AUTOSAR XML (schema 00046)
package /ComponentTypes
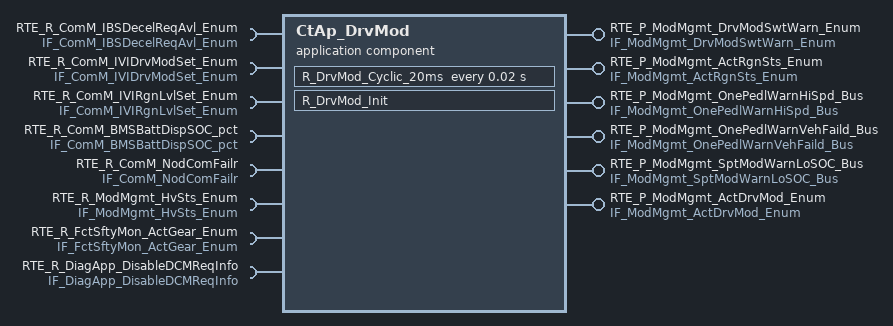
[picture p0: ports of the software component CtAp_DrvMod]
  application sw component type CtAp_DrvMod
    5 x require port:
      RTE_R_ComM_IBSDecelReqAvl_Enum: nonqueued-receiver-com-spec{data-element=tec_ComM_IBSDecelReqAvl_Enum, filter=data-filter-type=ALWAYS, init-value=0}, required-interface=IF_ComM_IBSDecelReqAvl_Enum
      RTE_R_ComM_IVIDrvModSet_Enum: nonqueued-receiver-com-spec{data-element=tec_ComM_IVIDrvModSet_Enum, filter=data-filter-type=ALWAYS, init-value=0}, required-interface=IF_ComM_IVIDrvModSet_Enum
      RTE_R_ComM_IVIRgnLvlSet_Enum: nonqueued-receiver-com-spec{data-element=tec_ComM_IVIRgnLvlSet_Enum, filter=data-filter-type=ALWAYS, init-value=0}, required-interface=IF_ComM_IVIRgnLvlSet_Enum
      RTE_R_ComM_BMSBattDispSOC_pct: nonqueued-receiver-com-spec{data-element=tec_ComM_BMSBattDispSOC_pct, filter=data-filter-type=ALWAYS, init-value=0}, required-interface=IF_ComM_BMSBattDispSOC_pct
      RTE_R_ComM_NodComFailr: required-interface=IF_ComM_NodComFailr
        required-com-specs:
          data-element=tec_ComM_SGWNodComFailr_Flg, filter=data-filter-type=ALWAYS, init-value=0
          data-element=tec_ComM_CGWNodComFailr_Flg, filter=data-filter-type=ALWAYS, init-value=0
          data-element=tec_ComM_TCUNodComFailr_Flg, filter=data-filter-type=ALWAYS, init-value=0
          data-element=tec_ComM_BCMNodComFailr_Flg, filter=data-filter-type=ALWAYS, init-value=0
          data-element=tec_ComM_PRNDNodComFailr_Flg, filter=data-filter-type=ALWAYS, init-value=0
          data-element=tec_ComM_IVINodComFailr_Flg, filter=data-filter-type=ALWAYS, init-value=0
          data-element=tec_ComM_DCDCNodComFailr_Flg, filter=data-filter-type=ALWAYS, init-value=0
          data-element=tec_ComM_OBCNodComFailr_Flg, filter=data-filter-type=ALWAYS, init-value=0
          data-element=tec_ComM_CHIBSNodComFailr_Flg, filter=data-filter-type=ALWAYS, init-value=0
          data-element=tec_ComM_MCUNodComFailr_Flg, filter=data-filter-type=ALWAYS, init-value=0
          data-element=tec_ComM_EVCOMNodComFailr_Flg, filter=data-filter-type=ALWAYS, init-value=0
          data-element=tec_ComM_EPTIBSNodComFailr_Flg, filter=data-filter-type=ALWAYS, init-value=0
          data-element=tec_ComM_DCMNodComFailr_Flg, filter=data-filter-type=ALWAYS, init-value=0
          data-element=tec_ComM_BMSNodComFailr_Flg, filter=data-filter-type=ALWAYS, init-value=0
          data-element=tec_ComM_ACUNodComFailr_Flg, filter=data-filter-type=ALWAYS, init-value=0
          data-element=tec_ComM_APTCNodComFailr_Flg, filter=data-filter-type=ALWAYS, init-value=0
          data-element=tec_ComM_ADCUNodComFailr_Flg, filter=data-filter-type=ALWAYS, init-value=0
          data-element=tec_ComM_DCMRRNodComFailr_Flg, filter=data-filter-type=ALWAYS, init-value=0
          data-element=tec_ComM_DCMRLNodComFailr_Flg, filter=data-filter-type=ALWAYS, init-value=0
          data-element=tec_ComM_DCMFRNodComFailr_Flg, filter=data-filter-type=ALWAYS, init-value=0
          data-element=tec_ComM_DCMFLNodComFailr_Flg, filter=data-filter-type=ALWAYS, init-value=0
          data-element=tec_ComM_SGWCHNodComFailr_Flg, init-value=0
    6 x provide port:
      RTE_P_ModMgmt_DrvModSwtWarn_Enum: nonqueued-sender-com-spec{data-element=tec_ModMgmt_DrvModSwtWarn_Enum, init-value=0}, provided-interface=IF_ModMgmt_DrvModSwtWarn_Enum
      RTE_P_ModMgmt_ActRgnSts_Enum: nonqueued-sender-com-spec{data-element=tec_ModMgmt_ActRgnSts_Enum, init-value=0}, provided-interface=IF_ModMgmt_ActRgnSts_Enum
      RTE_P_ModMgmt_OnePedlWarnHiSpd_Bus: nonqueued-sender-com-spec{data-element=tec_ModMgmt_OnePedlWarnHiSpd_Bus, init-value=fields=[ModMgmt_MonStatOnePedlWarnHiSpd:0, ModMgmt_MonResOnePedlWarnHiSpd:0, ModMgmt_ErrStatOnePedlWarnHiSpd:0, ModMgmt_ErrResOnePedlWarnHiSpd:0]}, provided-interface=IF_ModMgmt_OnePedlWarnHiSpd_Bus
      RTE_P_ModMgmt_OnePedlWarnVehFaild_Bus: nonqueued-sender-com-spec{data-element=tec_ModMgmt_OnePedlWarnVehFaild_Bus, init-value=fields=[ModMgmt_MonStatOnePedlWarnVehFaild:0, ModMgmt_MonResOnePedlWarnVehFaild:0, ModMgmt_ErrStatOnePedlWarnVehFaild:0, ModMgmt_ErrResOnePedlWarnVehFaild:0]}, provided-interface=IF_ModMgmt_OnePedlWarnVehFaild_Bus
      RTE_P_ModMgmt_SptModWarnLoSOC_Bus: nonqueued-sender-com-spec{data-element=tec_ModMgmt_SptModWarnLoSOC_Bus, init-value=fields=[ModMgmt_MonStatSptModWarnLoSOC:0, ModMgmt_MonResSptModWarnLoSOC:0, ModMgmt_ErrStatSptModWarnLoSOC:0, ModMgmt_ErrResSptModWarnLoSOC:0]}, provided-interface=IF_ModMgmt_SptModWarnLoSOC_Bus
      RTE_P_ModMgmt_ActDrvMod_Enum: nonqueued-sender-com-spec{data-element=tec_ModMgmt_ActDrvMod_Enum, init-value=0}, provided-interface=IF_ModMgmt_ActDrvMod_Enum
    require port RTE_R_ModMgmt_HvSts_Enum: nonqueued-receiver-com-spec{data-element=tec_ModMgmt_HvSts_Enum, filter=data-filter-type=ALWAYS, init-value=0}, required-interface=IF_ModMgmt_HvSts_Enum
    provide/require port RTE_RP_ModMgmtInfo:
      nv-provide-com-spec{ram-block-init-value=fields=[ModMgmt_DrvModMemInfo_Enum:2, ModMgmt_ActRgnStsMemInfo_Enum:3], rom-block-init-value=fields=[ModMgmt_DrvModMemInfo_Enum:2, ModMgmt_ActRgnStsMemInfo_Enum:3], variable=tec_ModMgmtInfo}
      nv-require-com-spec{init-value=fields=[ModMgmt_DrvModMemInfo_Enum:2, ModMgmt_ActRgnStsMemInfo_Enum:3], variable=tec_ModMgmtInfo}
      provided-required-interface=IF_ModMgmtInfo
    require port RTE_R_FctSftyMon_ActGear_Enum: nonqueued-receiver-com-spec{data-element=tec_FctSftyMon_ActGear_Enum, filter=data-filter-type=ALWAYS, init-value=0}, required-interface=IF_FctSftyMon_ActGear_Enum
    require port RTE_R_DiagApp_DisableDCMReqInfo: nonqueued-receiver-com-spec{data-element=tec_DiagApp_DisableDCMReqInfo, filter=data-filter-type=ALWAYS, init-value=0}, required-interface=IF_DiagApp_DisableDCMReqInfo
    behavior CtAp_DrvMod_InternalBehavior
      timing event TMT_R_DrvMod_Cyclic_20ms: start-on-event=R_DrvMod_Cyclic_20ms, period=0.02
      init event CtAp_DrvMod_InitEvent: start-on-event=R_DrvMod_Init
      runnable R_DrvMod_Cyclic_20ms
        data-receive-point-by-arguments:
          11 x access:
            REC_RTE_R_ComM_BMSBattDispSOC_pct_tec_ComM_BMSBattDispSOC_pct: accessed-variable=RTE_R_ComM_BMSBattDispSOC_pct.tec_ComM_BMSBattDispSOC_pct
            REC_RTE_R_ComM_IBSDecelReqAvl_Enum_tec_ComM_IBSDecelReqAvl_Enum: accessed-variable=RTE_R_ComM_IBSDecelReqAvl_Enum.tec_ComM_IBSDecelReqAvl_Enum
            REC_RTE_R_ComM_IVIDrvModSet_Enum_tec_ComM_IVIDrvModSet_Enum: accessed-variable=RTE_R_ComM_IVIDrvModSet_Enum.tec_ComM_IVIDrvModSet_Enum
            REC_RTE_R_ComM_IVIRgnLvlSet_Enum_tec_ComM_IVIRgnLvlSet_Enum: accessed-variable=RTE_R_ComM_IVIRgnLvlSet_Enum.tec_ComM_IVIRgnLvlSet_Enum
            REC_RTE_R_ComM_NodComFailr_tec_ComM_BMSNodComFailr_Flg: accessed-variable=RTE_R_ComM_NodComFailr.tec_ComM_BMSNodComFailr_Flg
            REC_RTE_R_ComM_NodComFailr_tec_ComM_CHIBSNodComFailr_Flg: accessed-variable=RTE_R_ComM_NodComFailr.tec_ComM_CHIBSNodComFailr_Flg
            REC_RTE_R_ComM_NodComFailr_tec_ComM_IVINodComFailr_Flg: accessed-variable=RTE_R_ComM_NodComFailr.tec_ComM_IVINodComFailr_Flg
            REC_RTE_R_ModMgmt_HvSts_Enum_tec_ModMgmt_HvSts_Enum: accessed-variable=RTE_R_ModMgmt_HvSts_Enum.tec_ModMgmt_HvSts_Enum
            REC_RTE_RP_ModMgmtInfo_tec_ModMgmtInfo: accessed-variable=RTE_RP_ModMgmtInfo.tec_ModMgmtInfo
            REC_RTE_R_FctSftyMon_ActGear_Enum_tec_FctSftyMon_ActGear_Enum: accessed-variable=RTE_R_FctSftyMon_ActGear_Enum.tec_FctSftyMon_ActGear_Enum
            REC_RTE_R_DiagApp_DisableDCMReqInfo_tec_DiagApp_DisableDCMReqInfo: accessed-variable=RTE_R_DiagApp_DisableDCMReqInfo.tec_DiagApp_DisableDCMReqInfo
        data-send-points:
          7 x access:
            SEND_RTE_P_ModMgmt_ActDrvMod_Enum_tec_ModMgmt_ActDrvMod_Enum: accessed-variable=RTE_P_ModMgmt_ActDrvMod_Enum.tec_ModMgmt_ActDrvMod_Enum
            SEND_RTE_P_ModMgmt_ActRgnSts_Enum_tec_ModMgmt_ActRgnSts_Enum: accessed-variable=RTE_P_ModMgmt_ActRgnSts_Enum.tec_ModMgmt_ActRgnSts_Enum
            SEND_RTE_P_ModMgmt_DrvModSwtWarn_Enum_tec_ModMgmt_DrvModSwtWarn_Enum: accessed-variable=RTE_P_ModMgmt_DrvModSwtWarn_Enum.tec_ModMgmt_DrvModSwtWarn_Enum
            SEND_RTE_P_ModMgmt_OnePedlWarnHiSpd_Bus_tec_ModMgmt_OnePedlWarnHiSpd_Bus: accessed-variable=RTE_P_ModMgmt_OnePedlWarnHiSpd_Bus.tec_ModMgmt_OnePedlWarnHiSpd_Bus
            SEND_RTE_P_ModMgmt_OnePedlWarnVehFaild_Bus_tec_ModMgmt_OnePedlWarnVehFaild_Bus: accessed-variable=RTE_P_ModMgmt_OnePedlWarnVehFaild_Bus.tec_ModMgmt_OnePedlWarnVehFaild_Bus
            SEND_RTE_P_ModMgmt_SptModWarnLoSOC_Bus_tec_ModMgmt_SptModWarnLoSOC_Bus: accessed-variable=RTE_P_ModMgmt_SptModWarnLoSOC_Bus.tec_ModMgmt_SptModWarnLoSOC_Bus
            SEND_RTE_RP_ModMgmtInfo_tec_ModMgmtInfo: accessed-variable=RTE_RP_ModMgmtInfo.tec_ModMgmtInfo
      runnable R_DrvMod_Init
  swc implementation CtAp_DrvMod_Implementation: behavior=CtAp_DrvMod_InternalBehavior
